# i2c_reva_me55 register map
Registers are 32-bit, access not given, no defined reset value unless marked. A register's access mark holds for its fields unless they carry their own. Offsets are from the block's base; lines under a group give offsets from that group; [hi:lo] are bit positions; {n}, {i} and the like mark numbered series; 'fields as' and 'values as' point back to an identical list; <NAME> marks a mode.

## Memory map
0x4001D000 I2C0 size 0x1000 — Inter-Integrated Circuit.

## Interrupts
13 I2C0 — I2C0 IRQ

## I2C0 — Inter-Integrated Circuit.
Base 0x4001D000
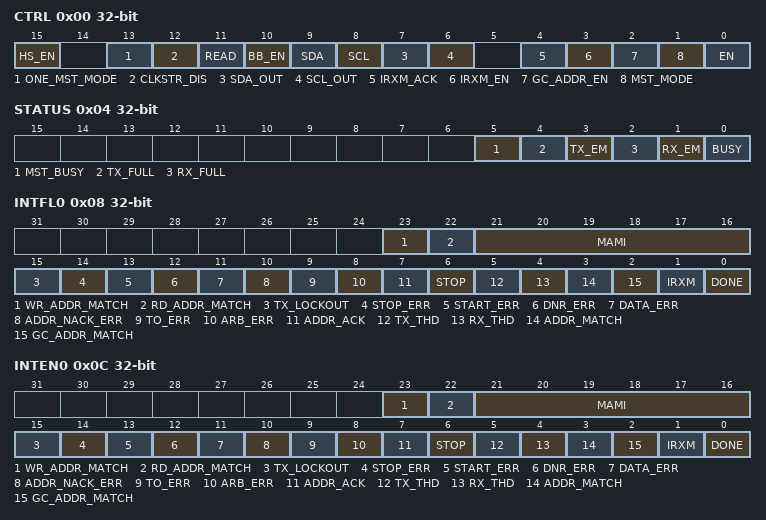
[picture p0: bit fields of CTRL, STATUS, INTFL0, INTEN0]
0x00 CTRL access per field — Control Register0.
  [15] HS_EN rw — High speed mode enable
  [13] ONE_MST_MODE rw — SCL Push-Pull Mode. This bit controls whether SCL is operated in a the I2C standard open-drain mode, or in a non-standard push-pull mode where the Hi-Z output isreplaced with Drive-1. The non-standard mode should only be used when operating as a master and communicating with slaves that are guaranteed to never drive SCL low.
    0=dis (Standard open-drain operation: drive low for 0, Hi-Z for 1); 1=en (Non-standard push-pull operation: drive low for 0, drive high for 1)
  [12] CLKSTR_DIS rw — This bit will disable slave clock stretching when set.
    0=en (Slave clock stretching enabled.); 1=dis (Slave clock stretching disabled.)
  [11] READ ro — Read. This bit reflects the R/W bit of an address match (AMI = 1) or general call match (GCI = 1). This bit is valid 3 cycles after the relevant interrupt bit is set.
    0=write; 1=read
  [10] BB_EN rw — Software Output Enable.
    0=outputs_disable (I2C Outputs SCLO and SDAO disabled.); 1=outputs_enable (I2C Outputs SCLO and SDAO enabled.)
  [9] SDA ro — SDA status. This bit reflects the logic gate of SDA signal.
  [8] SCL ro — SCL status. This bit reflects the logic gate of SCL signal.
  [7] SDA_OUT rw — SDA Output. This bits control SDA output when SWOE = 1.
    0=drive_sda_low; 1=release_sda
  [6] SCL_OUT rw — SCL Output. This bits control SCL output when SWOE =1.
    0=drive_scl_low; 1=release_scl
  [4] IRXM_ACK rw — Data Acknowledge. This bit defines the acknowledge bit returned by the I2C receiver while IRXM = 1 HW forces ACK to 0 when IRXM = 0.
    0=ack (return ACK (pulling SDA LOW).); 1=nack (return NACK (leaving SDA HIGH).)
  [3] IRXM_EN rw — Interactive Receive Mode.
    0=dis (Disable Interactive Receive Mode.); 1=en (Enable Interactive Receive Mode.)
  [2] GC_ADDR_EN rw — General Call Address Enable.
    0=dis (Ignore Gneral Call Address.); 1=en (Acknowledge general call address.)
  [1] MST_MODE rw — Master Mode Enable.
    0=slave_mode; 1=master_mode
  [0] EN rw — I2C Enable.
    0=dis (Disable I2C.); 1=en (enable I2C.)
0x04 STATUS
  [5] MST_BUSY ro — Clock Mode.
    0=not_actively_driving_scl_clock (Device not actively driving SCL clock cycles.); 1=actively_driving_scl_clock (Device operating as master and actively driving SCL clock cycles.)
  [4] TX_FULL
    0=not_empty; 1=empty
  [3] TX_EM — TX Empty.
    0=not_empty; 1=empty
  [2] RX_FULL ro
    0=not_full; 1=full
  [1] RX_EM ro — RX empty.
    0=not_empty; 1=empty
  [0] BUSY ro — Bus Status.
    0=idle (I2C Bus Idle.); 1=busy (I2C Bus Busy.)
0x08 INTFL0 — Interrupt Status Register.
  [23] WR_ADDR_MATCH — Slave Write Address Match Interrupt
  [22] RD_ADDR_MATCH — Slave Read Address Match Interrupt
  [21:16] MAMI — Multiple Address Match Interrupt
  [15] TX_LOCKOUT — Transmit Lock Out Interrupt.
  [14] STOP_ERR — Stop Error Interrupt.
    0=inactive (No Interrupt is Pending.); 1=pending (An interrupt is pending.)
  [13] START_ERR — Start Error Interrupt.
    values as STOP_ERR
  [12] DNR_ERR — Do Not Respond Error Interrupt.
    values as STOP_ERR
  [11] DATA_ERR — Data NACK Error Interrupt.
    values as STOP_ERR
  [10] ADDR_NACK_ERR — Address NACK Error Interrupt.
    values as STOP_ERR
  [9] TO_ERR — timeout Error Interrupt.
    values as STOP_ERR
  [8] ARB_ERR — Arbritation error Interrupt.
    values as STOP_ERR
  [7] ADDR_ACK — Address Acknowledge Interrupt.
    values as STOP_ERR
  [6] STOP — STOP Interrupt.
    0=inactive (No interrupt is pending.); 1=pending (An interrupt is pending. TX_FIFO has equal or less bytes than the threshold.)
  [5] TX_THD — Transmit Threshold Interrupt. This bit is automaticcaly cleared when TX_FIFO is above the threshold level.
    values as STOP
  [4] RX_THD — Receive Threshold Interrupt. This bit is automaticcaly cleared when RX_FIFO is below the threshold level.
    0=inactive (No interrupt is pending.); 1=pending (An interrupt is pending. RX_FIFO equal or more bytes than the threshold.)
  [3] ADDR_MATCH — Slave Address Match Interrupt.
    values as STOP_ERR
  [2] GC_ADDR_MATCH — Slave General Call Address Match Interrupt.
    values as STOP_ERR
  [1] IRXM — Interactive Receive Interrupt.
    values as STOP_ERR
  [0] DONE — Transfer Done Interrupt.
    values as STOP_ERR
0x0C INTEN0 rw — Interrupt Enable Register.
  [23] WR_ADDR_MATCH — Slave Write Address Match Interrupt
  [22] RD_ADDR_MATCH — Slave Read Address Match Interrupt
  [21:16] MAMI — Multiple Address Match Interrupt
  [15] TX_LOCKOUT — TX FIFO Locked Out Interrupt.
  [14] STOP_ERR — Out of Sequence STOP condition detected interrupt.
    0=dis (Interrupt disabled.); 1=en (Interrupt enabled.)
  [13] START_ERR — Out of Sequence START condition detected interrupt.
    0=dis (Interrupt disabled.); 1=en (Interrupt enabled.)
  [12] DNR_ERR — Slave Mode Do Not Respond Interrupt.
    0=dis (Interrupt disabled.); 1=en (Interrupt enabled.)
  [11] DATA_ERR — Master Mode Data NACK Received Interrupt.
    0=dis (Interrupt disabled.); 1=en (Interrupt enabled.)
  [10] ADDR_NACK_ERR — Master Mode Address NACK Received Interrupt.
    0=dis (Interrupt disabled.); 1=en (Interrupt enabled.)
  [9] TO_ERR — Timeout Error Interrupt Enable.
    0=dis (Interrupt disabled.); 1=en (Interrupt enabled.)
  [8] ARB_ERR — Master Mode Arbitration Lost Interrupt.
    0=dis (Interrupt disabled.); 1=en (Interrupt enabled.)
  [7] ADDR_ACK — Received Address ACK from Slave Interrupt.
    0=dis (Interrupt disabled.); 1=en (Interrupt enabled.)
  [6] STOP — Stop Interrupt Enable
    0=dis (Interrupt disabled.); 1=en (Interrupt enabled when STOP = 1.)
  [5] TX_THD — TX FIFO Below Treshold Level Interrupt Enable.
    0=dis (Interrupt disabled.); 1=en (Interrupt enabled.)
  [4] RX_THD — RX FIFO Above Treshold Level Interrupt Enable.
    0=dis (Interrupt disabled.); 1=en (Interrupt enabled.)
  [3] ADDR_MATCH — Slave mode incoming address match interrupt.
    0=dis (Interrupt disabled.); 1=en (Interrupt enabled when ADDR_MATCH = 1.)
  [2] GC_ADDR_MATCH — Slave mode general call address match received input enable.
    0=dis (Interrupt disabled.); 1=en (Interrupt enabled when GEN_CTRL_ADDR = 1.)
  [1] IRXM
    0=dis (Interrupt disabled.); 1=en (Interrupt enabled when RX_MODE = 1.)
  [0] DONE — Transfer Done Interrupt Enable.
    0=dis (Interrupt disabled.); 1=en (Interrupt enabled when DONE = 1.)
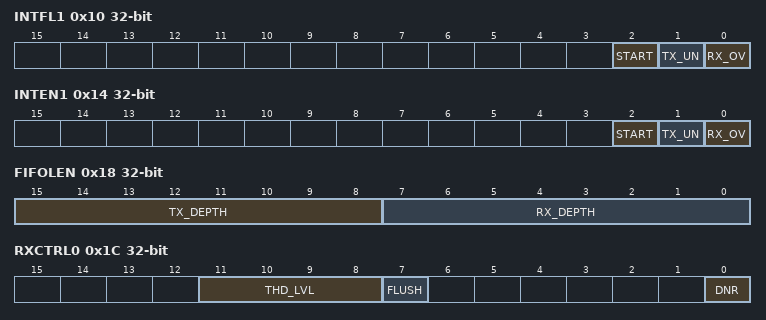
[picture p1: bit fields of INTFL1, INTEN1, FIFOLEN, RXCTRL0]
0x10 INTFL1 — Interrupt Status Register 1.
  [2] START — START Condition Status Flag.
  [1] TX_UN — Transmit Underflow Interrupt. When operating as a slave transmitter, this bit is set when you reach the first data bit and the TX FIFO is empty and the master is still asking for more data (i.e the master hasn't sent a NACK yet).
    values as INTFL0.STOP_ERR
  [0] RX_OV — Receiver Overflow Interrupt. When operating as a slave receiver, this bit is set when you reach the first data bit and the RX FIFO and shift register are both full.
    values as INTFL0.STOP_ERR
0x14 INTEN1 rw — Interrupt Staus Register 1.
  [2] START — START Condition Interrupt Enable.
  [1] TX_UN — Transmit Underflow Interrupt Enable.
    0=dis (No Interrupt is Pending.); 1=en (An interrupt is pending.)
  [0] RX_OV — Receiver Overflow Interrupt Enable.
    values as TX_UN
0x18 FIFOLEN ro — FIFO Configuration Register.
  [15:8] TX_DEPTH — Transmit FIFO Length.
  [7:0] RX_DEPTH — Receive FIFO Length.
0x1C RXCTRL0 — Receive Control Register 0.
  [11:8] THD_LVL — Receive FIFO Threshold. These bits define the RX_FIFO interrupt threshold.
  [7] FLUSH — Receive FIFO Flush. This bit is automatically cleared to 0 after the operation. Setting this bit to 1 will affect RX_FIFO status.
    0=not_flushed (FIFO not flushed.); 1=Flush RX_FIFO
  [0] DNR — Do Not Respond.
    0=respond (Always respond to address match.); 1=not_respond_rx_fifo_empty (Do not respond to address match when RX_FIFO is not empty.)
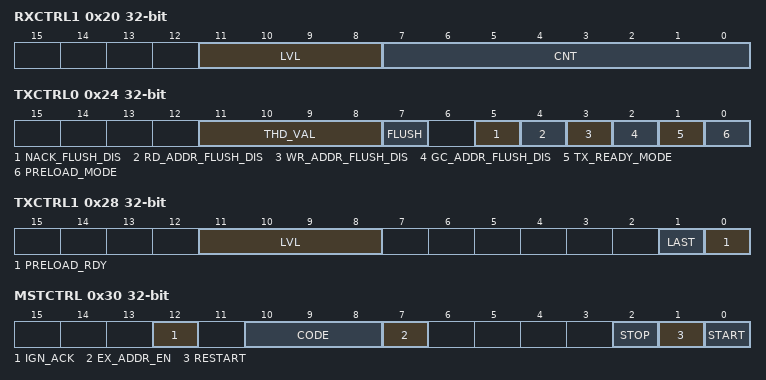
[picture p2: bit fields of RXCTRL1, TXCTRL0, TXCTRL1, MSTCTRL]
0x20 RXCTRL1 — Receive Control Register 1.
  [11:8] LVL ro — Receive FIFO Count. These bits reflect the number of byte in the RX_FIFO. These bits are flushed when I2CEN = 0.
  [7:0] CNT — Receive Count Bits. These bits define the number of bytes to be received in a transaction, except for the case RXCNT = 0. RXCNT = 0 means 256 bytes to be received in a transaction.
0x24 TXCTRL0 — Transmit Control Register 0.
  [11:8] THD_VAL — Transmit FIFO Threshold. These bits define the TX_FIFO interrupt threshold.
  [7] FLUSH — Transmit FIFO Flush. This bit is automatically cleared to 0 after the operation.
    0=not_flushed (FIFO not flushed.); 1=Flush TX_FIFO
  [5] NACK_FLUSH_DIS — TX FIFO received NACK Auto Flush Disable.
    0=en (Enabled.); 1=dis (Disabled.)
  [4] RD_ADDR_FLUSH_DIS — TX FIFO Slave Address Match Read Auto Flush Disable.
    0=en (Enabled.); 1=dis (Disabled.)
  [3] WR_ADDR_FLUSH_DIS — TX FIFO Slave Address Match Write Auto Flush Disable.
    0=en (Enabled.); 1=dis (Disabled.)
  [2] GC_ADDR_FLUSH_DIS — TX FIFO General Call Address Match Auto Flush Disable.
    0=en (Enabled.); 1=dis (Disabled.)
  [1] TX_READY_MODE — Transmit FIFO Ready Manual Mode.
    0=en (HW control of I2CTXRDY enabled.); 1=dis (HW control of I2CTXRDY disabled.)
  [0] PRELOAD_MODE — Transmit FIFO Preaload Mode. Setting this bit will allow for high speed application to preload the transmit FIFO prior to Slave Address Match.
0x28 TXCTRL1 — Transmit Control Register 1.
  [11:8] LVL ro — Transmit FIFO Count. These bits reflect the number of bytes in the TX_FIFO.
  [1] LAST — Transmit Last.
  [0] PRELOAD_RDY — Transmit FIFO Preload Ready.
0x2C FIFO — Data Register.
  [7:0] DATA — Data is read from or written to this location. Transmit and receive FIFO are separate but both are addressed at this location.
0x30 MSTCTRL — Master Control Register.
  [12] IGN_ACK — Master Ignore Acknowledge.
  [10:8] CODE — Master Code.
  [7] EX_ADDR_EN — Slave Extend Address Select.
    0=7_bits_address (7-bit address.); 1=10_bits_address (10-bit address.)
  [2] STOP — Setting this bit to 1 will generate a STOP condition.
  [1] RESTART — Setting this bit to 1 will generate a repeated START.
  [0] START — Setting this bit to 1 will start a master transfer.
0x34 CLKLO — Clock Low Register.
  [8:0] LO — Clock low. In master mode, these bits define the SCL low period. In slave mode, these bits define the time SCL will be held low after data is outputted.
0x38 CLKHI — Clock high Register.
  [8:0] HI — Clock High. In master mode, these bits define the SCL high period.
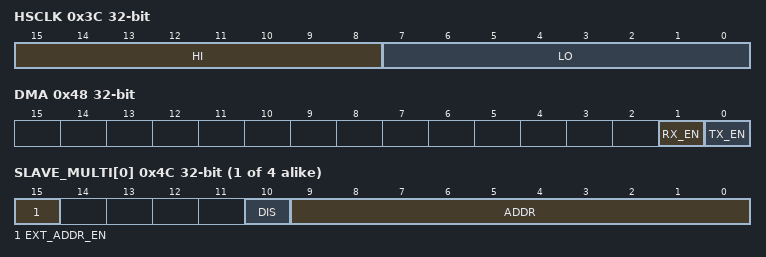
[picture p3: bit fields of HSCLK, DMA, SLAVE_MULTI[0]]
0x3C HSCLK — Clock high Register.
  [15:8] HI — Clock High. This field sets the Hs-Mode clock high count. In Slave mode, this is the time SCL is held high after data is output on SDA
  [7:0] LO — Clock Low. This field sets the Hs-Mode clock low count. In Slave mode, this is the time SCL is held low after data is output on SDA.
0x40 TIMEOUT
  [15:0] SCL_TO_VAL — Timeout
0x48 DMA
  [1] RX_EN — RX channel enable.
    0=dis (Disable.); 1=en (Enable.)
  [0] TX_EN — TX channel enable.
    0=dis (Disable.); 1=en (Enable.)
{0x4C+4i} SLAVE_MULTI[{i}] (i=0..3) rw (alternate view of SLAVE0) — Slave Address Register.
  [15] EXT_ADDR_EN — Extended Address Select.
    values as MSTCTRL.EX_ADDR_EN
  [10] DIS — Slave Disable.
  [9:0] ADDR — Slave Address.
{0x4C+4i} SLAVE{i} (i=0..3) — Slave Address Register.
